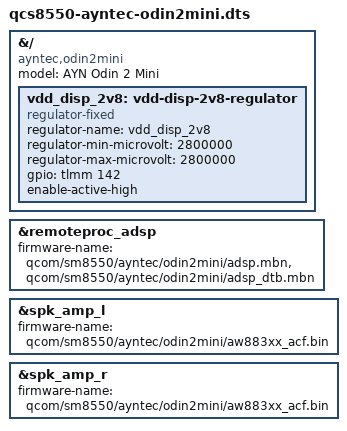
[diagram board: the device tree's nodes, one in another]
// SPDX-License-Identifier: BSD-3-Clause
/*
 * Copyright (c) 2025, Teguh Sobirin.
 */

/dts-v1/;

#include <dt-bindings/gpio/gpio.h>
#include <dt-bindings/interrupt-controller/irq.h>
#include "qcs8550-ayntec-common.dtsi"

&{/} {
	model = "AYN Odin 2 Mini";
	compatible = "ayntec,odin2mini", "qcom,qcs8550", "qcom,sm8550";

	vdd_disp_2v8: vdd-disp-2v8-regulator {
		compatible = "regulator-fixed";
		regulator-name = "vdd_disp_2v8";

		regulator-min-microvolt = <2800000>;
		regulator-max-microvolt = <2800000>;

		gpio = <&tlmm 142 GPIO_ACTIVE_HIGH>;
		enable-active-high;
	};
};

/* There is an hdmi bridge on i2c_hub_0@48, but it is not currently supported */

&remoteproc_adsp {
	firmware-name = "qcom/sm8550/ayntec/odin2mini/adsp.mbn",
			"qcom/sm8550/ayntec/odin2mini/adsp_dtb.mbn";

	status = "okay";
};

&spk_amp_l {
	firmware-name = "qcom/sm8550/ayntec/odin2mini/aw883xx_acf.bin";
};

&spk_amp_r {
	firmware-name = "qcom/sm8550/ayntec/odin2mini/aw883xx_acf.bin";
};

